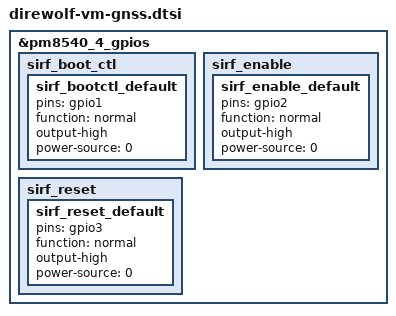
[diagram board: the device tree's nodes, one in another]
&pm8540_4_gpios {

	sirf_boot_ctl {
		sirf_bootctl_default: sirf_bootctl_default {
			pins = "gpio1";
			function = "normal";
			output-high;
			power-source = <0>;
		};
	};

	sirf_enable {
		sirf_enable_default: sirf_enable_default {
			pins = "gpio2";
			function = "normal";
			output-high;
			power-source = <0>;
		};
	};

	sirf_reset {
		sirf_reset_default: sirf_reset_default {
			pins = "gpio3";
			function = "normal";
			output-high;
			power-source = <0>;
		};
	};
};
